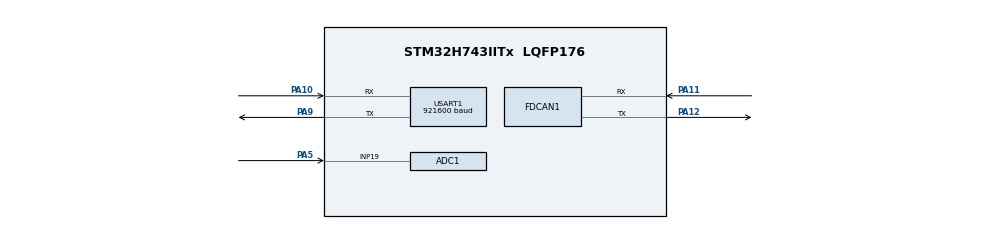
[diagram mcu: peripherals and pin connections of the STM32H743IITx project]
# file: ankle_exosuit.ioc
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ADC1.Channel-0\#ChannelRegularConversion=ADC_CHANNEL_19
ADC1.ClockPrescaler=ADC_CLOCK_ASYNC_DIV6
ADC1.ContinuousConvMode=ENABLE
ADC1.ConversionDataManagement=ADC_CONVERSIONDATA_DMA_CIRCULAR
ADC1.EOCSelection=ADC_EOC_SEQ_CONV
ADC1.NbrOfConversion=1
ADC1.NbrOfConversionFlag=1
ADC1.OffsetNumber-0\#ChannelRegularConversion=ADC_OFFSET_NONE
ADC1.OffsetSignedSaturation-0\#ChannelRegularConversion=DISABLE
ADC1.Overrun=ADC_OVR_DATA_OVERWRITTEN
ADC1.OversamplingMode=DISABLE
ADC1.Rank-0\#ChannelRegularConversion=1
ADC1.Resolution=ADC_RESOLUTION_12B
ADC1.SamplingTime-0\#ChannelRegularConversion=ADC_SAMPLETIME_387CYCLES_5
ADC1.master=1
CORTEX_M7.CPU_DCache=Disabled
CORTEX_M7.CPU_ICache=Disabled
Dma.ADC1.2.Direction=DMA_PERIPH_TO_MEMORY
Dma.ADC1.2.EventEnable=DISABLE
Dma.ADC1.2.FIFOMode=DMA_FIFOMODE_DISABLE
Dma.ADC1.2.Instance=DMA1_Stream4
Dma.ADC1.2.MemDataAlignment=DMA_MDATAALIGN_HALFWORD
Dma.ADC1.2.MemInc=DMA_MINC_ENABLE
Dma.ADC1.2.Mode=DMA_CIRCULAR
Dma.ADC1.2.PeriphDataAlignment=DMA_PDATAALIGN_HALFWORD
Dma.ADC1.2.PeriphInc=DMA_PINC_DISABLE
Dma.ADC1.2.Polarity=HAL_DMAMUX_REQ_GEN_RISING
Dma.ADC1.2.Priority=DMA_PRIORITY_MEDIUM
Dma.ADC1.2.RequestNumber=1
Dma.ADC1.2.SignalID=NONE
Dma.ADC1.2.SyncEnable=DISABLE
Dma.ADC1.2.SyncPolarity=HAL_DMAMUX_SYNC_NO_EVENT
Dma.ADC1.2.SyncRequestNumber=1
Dma.ADC1.2.SyncSignalID=NONE
Dma.Request0=USART1_TX
Dma.Request1=USART1_RX
Dma.Request2=ADC1
Dma.USART1_RX.1.Direction=DMA_PERIPH_TO_MEMORY
Dma.USART1_RX.1.EventEnable=DISABLE
Dma.USART1_RX.1.FIFOMode=DMA_FIFOMODE_DISABLE
Dma.USART1_RX.1.Instance=DMA1_Stream1
Dma.USART1_RX.1.MemDataAlignment=DMA_MDATAALIGN_BYTE
Dma.USART1_RX.1.MemInc=DMA_MINC_ENABLE
Dma.USART1_RX.1.Mode=DMA_NORMAL
Dma.USART1_RX.1.PeriphDataAlignment=DMA_PDATAALIGN_BYTE
Dma.USART1_RX.1.PeriphInc=DMA_PINC_DISABLE
Dma.USART1_RX.1.Polarity=HAL_DMAMUX_REQ_GEN_RISING
Dma.USART1_RX.1.Priority=DMA_PRIORITY_LOW
Dma.USART1_RX.1.RequestNumber=1
Dma.USART1_RX.1.SignalID=NONE
Dma.USART1_RX.1.SyncEnable=DISABLE
Dma.USART1_RX.1.SyncPolarity=HAL_DMAMUX_SYNC_NO_EVENT
Dma.USART1_RX.1.SyncRequestNumber=1
Dma.USART1_RX.1.SyncSignalID=NONE
Dma.USART1_TX.0.Direction=DMA_MEMORY_TO_PERIPH
Dma.USART1_TX.0.EventEnable=DISABLE
Dma.USART1_TX.0.FIFOMode=DMA_FIFOMODE_DISABLE
Dma.USART1_TX.0.Instance=DMA1_Stream0
Dma.USART1_TX.0.MemDataAlignment=DMA_MDATAALIGN_BYTE
Dma.USART1_TX.0.MemInc=DMA_MINC_ENABLE
Dma.USART1_TX.0.Mode=DMA_NORMAL
Dma.USART1_TX.0.PeriphDataAlignment=DMA_PDATAALIGN_BYTE
Dma.USART1_TX.0.PeriphInc=DMA_PINC_DISABLE
Dma.USART1_TX.0.Polarity=HAL_DMAMUX_REQ_GEN_RISING
Dma.USART1_TX.0.Priority=DMA_PRIORITY_LOW
Dma.USART1_TX.0.RequestNumber=1
Dma.USART1_TX.0.SignalID=NONE
Dma.USART1_TX.0.SyncEnable=DISABLE
Dma.USART1_TX.0.SyncPolarity=HAL_DMAMUX_SYNC_NO_EVENT
Dma.USART1_TX.0.SyncRequestNumber=1
Dma.USART1_TX.0.SyncSignalID=NONE
FDCAN1.DataPrescaler=5
FDCAN1.DataSyncJumpWidth=8
FDCAN1.DataTimeSeg1=11
FDCAN1.DataTimeSeg2=8
FDCAN1.NominalPrescaler=5
FDCAN1.NominalSyncJumpWidth=8
FDCAN1.NominalTimeSeg1=11
FDCAN1.NominalTimeSeg2=8
FDCAN1.RxFifo0ElmtsNbr=1
FDCAN1.StdFiltersNbr=1
FDCAN1.TxFifoQueueElmtsNbr=1
FREERTOS.BinarySemaphores01=bufferSemaphore,Dynamic,NULL
FREERTOS.INCLUDE_uxTaskGetStackHighWaterMark=1
FREERTOS.Mutexes01=motorData,Dynamic,NULL
FREERTOS.Tasks01=detect,0,128,detect_Task,As weak,NULL,Dynamic,NULL,NULL;motor,3,128,motor_Task,As weak,NULL,Dynamic,NULL,NULL;profile,2,128,profile_Task,As weak,NULL,Dynamic,NULL,NULL
FREERTOS.configCHECK_FOR_STACK_OVERFLOW=2
FREERTOS.configTOTAL_HEAP_SIZE=20480
Mcu.Family=STM32H7
Mcu.Name=STM32H743IITx
Mcu.Package=LQFP176
NVIC.DMA1_Stream0_IRQn=true\:5\:0\:false\:false\:true\:true\:false\:true\:true
NVIC.DMA1_Stream1_IRQn=true\:5\:0\:false\:false\:true\:true\:false\:true\:true
NVIC.DMA1_Stream4_IRQn=true\:5\:0\:false\:false\:true\:true\:false\:true\:true
NVIC.FDCAN1_IT0_IRQn=true\:5\:0\:false\:false\:true\:true\:true\:true\:true
NVIC.PriorityGroup=NVIC_PRIORITYGROUP_4
NVIC.TIM2_IRQn=true\:1\:0\:true\:false\:true\:false\:false\:true\:true
NVIC.TimeBase=TIM2_IRQn
NVIC.TimeBaseIP=TIM2
NVIC.USART1_IRQn=true\:6\:0\:true\:false\:true\:true\:true\:true\:true
PA10.GPIO_PuPd=GPIO_PULLUP
PA10.GPIO_Speed=GPIO_SPEED_FREQ_HIGH
PA10.Mode=Asynchronous
PA10.Signal=USART1_RX
PA11.GPIO_Speed=GPIO_SPEED_FREQ_HIGH
PA11.Mode=FDCAN_Activate
PA11.Signal=FDCAN1_RX
PA12.GPIO_Speed=GPIO_SPEED_FREQ_HIGH
PA12.Mode=FDCAN_Activate
PA12.Signal=FDCAN1_TX
PA13\ (JTMS/SWDIO).Mode=Serial_Wire
PA13\ (JTMS/SWDIO).Signal=DEBUG_JTMS-SWDIO
PA14\ (JTCK/SWCLK).Mode=Serial_Wire
PA14\ (JTCK/SWCLK).Signal=DEBUG_JTCK-SWCLK
PA5.Signal=ADCx_INP19
PA9.GPIO_Speed=GPIO_SPEED_FREQ_HIGH
PA9.Mode=Asynchronous
PA9.Signal=USART1_TX
PB10.GPIO_Label=ATK_MW8266D_UART_TX
PB10.GPIO_Speed=GPIO_SPEED_FREQ_HIGH
PB10.Signal=USART3_TX
PB11.GPIO_Label=ATK_MW8266D_UART_RX
PB11.GPIO_Speed=GPIO_SPEED_FREQ_HIGH
PB11.Signal=USART3_RX
PH0-OSC_IN\ (PH0).Mode=HSE-External-Oscillator
PH0-OSC_IN\ (PH0).Signal=RCC_OSC_IN
PH1-OSC_OUT\ (PH1).Mode=HSE-External-Oscillator
PH1-OSC_OUT\ (PH1).Signal=RCC_OSC_OUT
ProjectManager.HeapSize=0x1000
ProjectManager.StackSize=0x2000
ProjectManager.TargetToolchain=MDK-ARM V5
RCC.ADCFreq_Value=75000000
RCC.APB1Freq_Value=100000000
RCC.APB2Freq_Value=100000000
RCC.APB3Freq_Value=100000000
RCC.APB4Freq_Value=100000000
RCC.CortexFreq_Value=400000000
RCC.D1PPRE=RCC_APB3_DIV2
RCC.D2PPRE1=RCC_APB1_DIV2
RCC.D2PPRE2=RCC_APB2_DIV2
RCC.D3PPRE=RCC_APB4_DIV2
RCC.DIVM1=5
RCC.DIVM2=2
RCC.DIVN1=160
RCC.DIVN2=12
RCC.DIVQ1=8
RCC.HCLKFreq_Value=200000000
RCC.HPRE=RCC_HCLK_DIV2
RCC.PLL2FRACN=0
RCC.PLL3FRACN=0
RCC.PLLFRACN=0
RCC.PLLSourceVirtual=RCC_PLLSOURCE_HSE
RCC.SYSCLKFreq_VALUE=400000000
RCC.SYSCLKSource=RCC_SYSCLKSOURCE_PLLCLK
RCC.USBFreq_Value=100000000
SH.ADCx_INP19.0=ADC1_INP19,IN19-Single-Ended
USART1.BaudRate=921600
USART1.VirtualMode-Asynchronous=VM_ASYNC
VP_FREERTOS_VS_CMSIS_V1.Mode=CMSIS_V1
VP_SYS_VS_tim2.Mode=TIM2
board=custom

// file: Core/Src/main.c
/* USER CODE BEGIN Header */
/**
  ******************************************************************************
  * @file           : main.c
  * @brief          : Main program body
  ******************************************************************************
  * @attention
  *
  * Copyright (c) 2024 STMicroelectronics.
  * All rights reserved.
  *
  * This software is licensed under terms that can be found in the LICENSE file
  * in the root directory of this software component.
  * If no LICENSE file comes with this software, it is provided AS-IS.
  *
  ******************************************************************************
  */
/* USER CODE END Header */
#include "main.h"
#include "cmsis_os.h"
#include "adc.h"
#include "dma.h"
#include "fdcan.h"
#include "usart.h"
#include "gpio.h"

/* USER CODE BEGIN Includes */
#include "bsp_usart1.h"
#include "bsp_fdcan.h"
#include "globals.h"
/* USER CODE END Includes */

/* USER CODE BEGIN PV */
uint16_t ADC_ConvertedValue=0;
/* USER CODE END PV */

void SystemClock_Config(void);
void MX_FREERTOS_Init(void);

int main(void)
{

  /* MCU Configuration--------------------------------------------------------*/

  /* Reset of all peripherals, Initializes the Flash interface and the Systick. */
  HAL_Init();

  /* Configure the system clock */
  SystemClock_Config();

  /* Initialize all configured peripherals */
  MX_GPIO_Init();
  MX_DMA_Init();
  MX_USART1_UART_Init();
  MX_FDCAN1_Init();
  MX_ADC1_Init();
  /* USER CODE BEGIN 2 */
  HAL_UARTEx_ReceiveToIdle_DMA(&huart1,xUART1.BuffTemp,sizeof(xUART1.BuffTemp));
	HAL_ADC_Start_DMA(&hadc1, (uint32_t*)&ADC_ConvertedValue, sizeof(ADC_ConvertedValue));
  /* USER CODE END 2 */

  /* Call init function for freertos objects (in freertos.c) */
  MX_FREERTOS_Init();
  /* Start scheduler */
  osKernelStart();

  /* We should never get here as control is now taken by the scheduler */
  /* Infinite loop */
  while (1)
  {

  }
}

void SystemClock_Config(void)
{
  RCC_OscInitTypeDef RCC_OscInitStruct = {0};
  RCC_ClkInitTypeDef RCC_ClkInitStruct = {0};

  /** Supply configuration update enable
  */
  HAL_PWREx_ConfigSupply(PWR_LDO_SUPPLY);
  /** Configure the main internal regulator output voltage
  */
  __HAL_PWR_VOLTAGESCALING_CONFIG(PWR_REGULATOR_VOLTAGE_SCALE1);

  while(!__HAL_PWR_GET_FLAG(PWR_FLAG_VOSRDY)) {}
  /** Macro to configure the PLL clock source
  */
  __HAL_RCC_PLL_PLLSOURCE_CONFIG(RCC_PLLSOURCE_HSE);
  /** Initializes the RCC Oscillators according to the specified parameters
  * in the RCC_OscInitTypeDef structure.
  */
  RCC_OscInitStruct.OscillatorType = RCC_OSCILLATORTYPE_HSE;
  RCC_OscInitStruct.HSEState = RCC_HSE_ON;
  RCC_OscInitStruct.PLL.PLLState = RCC_PLL_ON;
  RCC_OscInitStruct.PLL.PLLSource = RCC_PLLSOURCE_HSE;
  RCC_OscInitStruct.PLL.PLLM = 5;
  RCC_OscInitStruct.PLL.PLLN = 160;
  RCC_OscInitStruct.PLL.PLLP = 2;
  RCC_OscInitStruct.PLL.PLLQ = 8;
  RCC_OscInitStruct.PLL.PLLR = 2;
  RCC_OscInitStruct.PLL.PLLRGE = RCC_PLL1VCIRANGE_2;
  RCC_OscInitStruct.PLL.PLLVCOSEL = RCC_PLL1VCOWIDE;
  RCC_OscInitStruct.PLL.PLLFRACN = 0;
  if (HAL_RCC_OscConfig(&RCC_OscInitStruct) != HAL_OK)
  {
    Error_Handler();
  }
  /** Initializes the CPU, AHB and APB buses clocks
  */
  RCC_ClkInitStruct.ClockType = RCC_CLOCKTYPE_HCLK|RCC_CLOCKTYPE_SYSCLK
                              |RCC_CLOCKTYPE_PCLK1|RCC_CLOCKTYPE_PCLK2
                              |RCC_CLOCKTYPE_D3PCLK1|RCC_CLOCKTYPE_D1PCLK1;
  RCC_ClkInitStruct.SYSCLKSource = RCC_SYSCLKSOURCE_PLLCLK;
  RCC_ClkInitStruct.SYSCLKDivider = RCC_SYSCLK_DIV1;
  RCC_ClkInitStruct.AHBCLKDivider = RCC_HCLK_DIV2;
  RCC_ClkInitStruct.APB3CLKDivider = RCC_APB3_DIV2;
  RCC_ClkInitStruct.APB1CLKDivider = RCC_APB1_DIV2;
  RCC_ClkInitStruct.APB2CLKDivider = RCC_APB2_DIV2;
  RCC_ClkInitStruct.APB4CLKDivider = RCC_APB4_DIV2;

  if (HAL_RCC_ClockConfig(&RCC_ClkInitStruct, FLASH_LATENCY_2) != HAL_OK)
  {
    Error_Handler();
  }
}

void HAL_TIM_PeriodElapsedCallback(TIM_HandleTypeDef *htim)
{
  if (htim->Instance == TIM2) {
    HAL_IncTick();
  }
}

void Error_Handler(void)
{
  __disable_irq();
  while (1)
  {
  }
}

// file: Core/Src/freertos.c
/* USER CODE BEGIN Header */
/**
  ******************************************************************************
  * File Name          : freertos.c
  * Description        : Code for freertos applications
  ******************************************************************************
  * @attention
  *
  * Copyright (c) 2024 STMicroelectronics.
  * All rights reserved.
  *
  * This software is licensed under terms that can be found in the LICENSE file
  * in the root directory of this software component.
  * If no LICENSE file comes with this software, it is provided AS-IS.
  *
  ******************************************************************************
  */
/* USER CODE END Header */

#include "FreeRTOS.h"
#include "task.h"
#include "main.h"
#include "cmsis_os.h"

/* USER CODE BEGIN Includes */
#include "bsp_usart1.h"
#include "globals.h"
/* USER CODE END Includes */

osThreadId detectHandle;
osThreadId motorHandle;
osThreadId profileHandle;
osMutexId motorDataHandle;
osSemaphoreId bufferSemaphoreHandle;

void detect_Task(void const * argument);
void motor_Task(void const * argument);
void profile_Task(void const * argument);

void MX_FREERTOS_Init(void); /* (MISRA C 2004 rule 8.1) */

/* GetIdleTaskMemory prototype (linked to static allocation support) */
void vApplicationGetIdleTaskMemory( StaticTask_t **ppxIdleTaskTCBBuffer, StackType_t **ppxIdleTaskStackBuffer, uint32_t *pulIdleTaskStackSize );

/* Hook prototypes */
void vApplicationStackOverflowHook(xTaskHandle xTask, signed char *pcTaskName);

/* USER CODE BEGIN 4 */
__weak void vApplicationStackOverflowHook(xTaskHandle xTask, signed char *pcTaskName)
{
   /* Run time stack overflow checking is performed if
   configCHECK_FOR_STACK_OVERFLOW is defined to 1 or 2. This hook function is
   called if a stack overflow is detected. */
	usart1_printf("����%s ���\r\n",pcTaskName);
}
/* USER CODE END 4 */

/* USER CODE BEGIN GET_IDLE_TASK_MEMORY */
static StaticTask_t xIdleTaskTCBBuffer;
static StackType_t xIdleStack[configMINIMAL_STACK_SIZE];

void vApplicationGetIdleTaskMemory( StaticTask_t **ppxIdleTaskTCBBuffer, StackType_t **ppxIdleTaskStackBuffer, uint32_t *pulIdleTaskStackSize )
{
  *ppxIdleTaskTCBBuffer = &xIdleTaskTCBBuffer;
  *ppxIdleTaskStackBuffer = &xIdleStack[0];
  *pulIdleTaskStackSize = configMINIMAL_STACK_SIZE;
  /* place for user code */
}
/* USER CODE END GET_IDLE_TASK_MEMORY */

void MX_FREERTOS_Init(void) {
  /* Create the mutex(es) */
  /* definition and creation of motorData */
  osMutexDef(motorData);
  motorDataHandle = osMutexCreate(osMutex(motorData));

  /* Create the semaphores(s) */
  /* definition and creation of bufferSemaphore */
  osSemaphoreDef(bufferSemaphore);
  bufferSemaphoreHandle = osSemaphoreCreate(osSemaphore(bufferSemaphore), 1);

  /* Create the thread(s) */
  /* definition and creation of detect */
  osThreadDef(detect, detect_Task, osPriorityNormal, 0, 128);
  detectHandle = osThreadCreate(osThread(detect), NULL);

  /* definition and creation of motor */
  osThreadDef(motor, motor_Task, osPriorityRealtime, 0, 128);
  motorHandle = osThreadCreate(osThread(motor), NULL);

  /* definition and creation of profile */
  osThreadDef(profile, profile_Task, osPriorityHigh, 0, 128);
  profileHandle = osThreadCreate(osThread(profile), NULL);

}

__weak void detect_Task(void const * argument)
{
  for(;;)
  {
    osDelay(1);
  }
}

__weak void motor_Task(void const * argument)
{
  for(;;)
  {
    osDelay(1);
  }
}

__weak void profile_Task(void const * argument)
{
  for(;;)
  {
    osDelay(1);
  }
}
